# CS32F031x register map
File version: 1.0
Registers are 32-bit, read-write, reset 0x0 unless marked. A register's access mark holds for its fields unless they carry their own. Offsets are from the block's base; [hi:lo] are bit positions; lines under a group give offsets from that group; {n}, {i} and the like mark numbered series.

## ADC — Analog-to-digital converter
Base 0x40012400
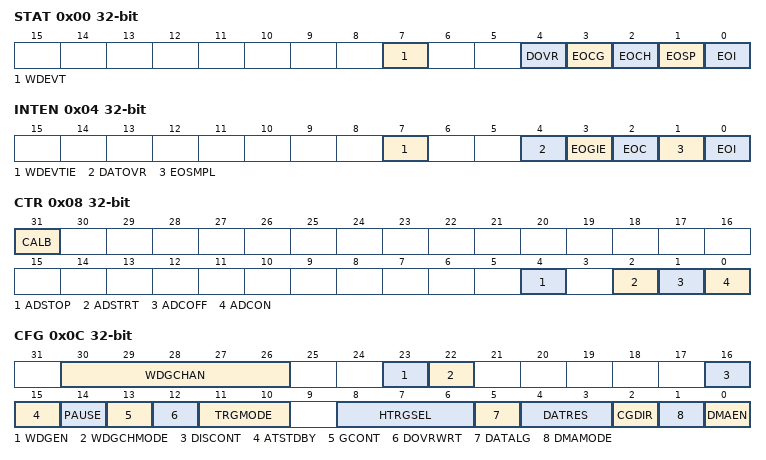
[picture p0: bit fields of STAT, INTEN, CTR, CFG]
0x00 STAT — ADC status register
  [7] WDEVT — analog watchdog event flag
  [4] DOVR — ADC data overrun flag
  [3] EOCG — End of conversion group flag
  [2] EOCH — End of channel conversion flag
  [1] EOSP — End of sampling phase flag
  [0] EOI — End of ADC initialization
0x04 INTEN — ADC interrupt enable register
  [7] WDEVTIE — analog watchdog event interrupt enable
  [4] DATOVR — ADC data overrun interrupt enable
  [3] EOGIE — End of conversion group interrupt enable
  [2] EOC — End of channel conversion interrupt enable
  [1] EOSMPL — End of sampling phase interrupt enable
  [0] EOI — End of ADC initialization interrupt enable
0x08 CTR — ADC general control register
  [31] CALB — ADC calibration control
  [4] ADSTOP — ADC stop conversion command
  [2] ADSTRT — ADC start conversion command
  [1] ADCOFF — ADC power off command
  [0] ADCON — ADC power on command
0x0C CFG — configuration register 1
  [30:26] WDGCHAN — Analog watchdog monitor channel selection
  [23] WDGEN — Analog watchdog enable
  [22] WDGCHMODE — Analog watchdog channel monitor mode
  [16] DISCONT — Discontinuous conversion mode
  [15] ATSTDBY — auto standby mode
  [14] PAUSE — conversion pause mode
  [13] GCONT — Group conversion Single/continuous mode
  [12] DOVRWRT — Coversion data overrun overwriten mode
  [11:10] TRGMODE — Coverstion Trigger mode selection
  [8:6] HTRGSEL — Hardware trigger source selection
  [5] DATALG — Coversion data format alignment
  [4:3] DATRES — Coversion data reselution
  [2] CGDIR — Coveration group sequence direction
  [1] DMAMODE — Direct memory access single/circle mode
  [0] DMAEN — Direct memory access enable
0x10 CLK reset 0x8000 — clock source register
  [31:30] CKSRC — ADC clock source selection
0x14 SMPLR — sampling time register
  [2:0] SMPLT — Sampling time selection
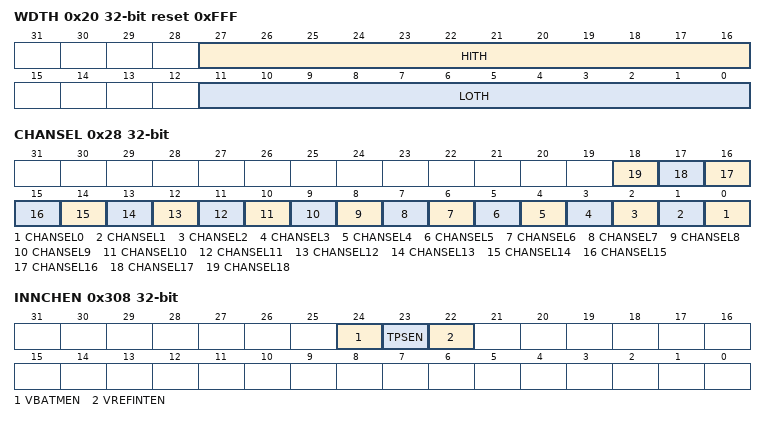
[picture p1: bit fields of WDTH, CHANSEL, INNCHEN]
0x20 WDTH reset 0xFFF — Analog watchdog threshold register
  [27:16] HITH — Analog watchdog higher threshold
  [11:0] LOTH — Analog watchdog lower threshold
0x28 CHANSEL — conversion channel selection register
  [n] CHANSEL{n} (n=0..18) — conversion channel selection x
0x40 OUTDAT ro — conversion output data register
  [15:0] OUTDAT — conversion output data
0x308 INNCHEN — internal conversion channel enable register
  [24] VBATMEN — VBAT monitor enable
  [23] TPSEN — Temperature sensor enable
  [22] VREFINTEN — VREFINT enable

## TIM15 — General-purpose-timers
Base 0x40014000
Same registers: TIM16 0x40014400, TIM17 0x40014800
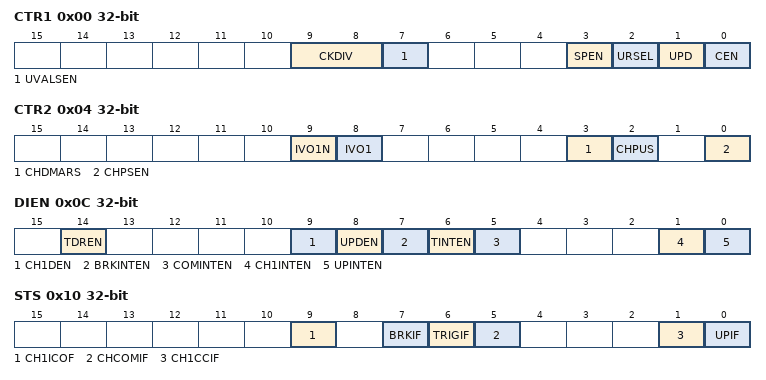
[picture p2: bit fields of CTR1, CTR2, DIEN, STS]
0x00 CTR1 — control register 1
  [9:8] CKDIV — Clock division
  [7] UVALSEN — UVAL shadow enable
  [3] SPEN — Single pulse enable
  [2] URSEL — Update request selection
  [1] UPD — Update disable
  [0] CEN — Counter enable
0x04 CTR2 — control register 2
  [9] IVO1N — Idle value output of channel 1 complementary
  [8] IVO1 — Idle value output of channel 1
  [3] CHDMARS — DMA request source of channel
  [2] CHPUS — Preload update source of channel
  [0] CHPSEN — Preload shadow enable of channel
0x0C DIEN — DMA and interrupt enable register
  [14] TDREN — Enable bit for trigger DMA request
  [9] CH1DEN — Enable bit for channel 1 DMA request
  [8] UPDEN — Enable bit for update DMA request
  [7] BRKINTEN — Enable bit for break interrupt
  [6] TINTEN — Enable bit for trigger interrupt
  [5] COMINTEN — Enable bit for COM event interrupt
  [1] CH1INTEN — Enable bit for channel 1 interrupt
  [0] UPINTEN — Enable bit for update interrupt
0x10 STS — status register
  [9] CH1ICOF — Channel 1 input capture overflow
  [7] BRKIF — Interrupt flag of break
  [6] TRIGIF — Interrupt flag of trigger
  [5] CHCOMIF — channel communication event interrupt flag
  [1] CH1CCIF — Channel 1 capture compare interrupt flag
  [0] UPIF — Interrupt flag of update
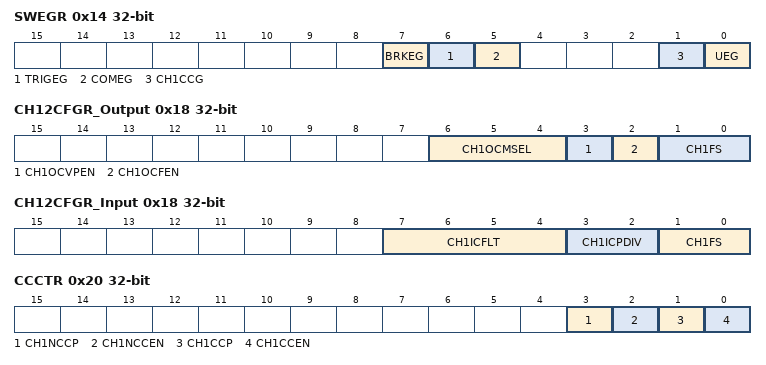
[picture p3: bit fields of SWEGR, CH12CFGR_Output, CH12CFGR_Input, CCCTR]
0x14 SWEGR wo — software event generation register
  [7] BRKEG — Break event generation
  [6] TRIGEG — Trigger event generation
  [5] COMEG — COM event generation
  [1] CH1CCG — Channel 1 capture compare event generation
  [0] UEG — Update event generation
0x18 CH12CFGR_Output — channel 1 and channel 2 configuration register (output mode)
  [6:4] CH1OCMSEL — Channel 1 output compare mode selection
  [3] CH1OCVPEN — Channel 1 output compare value preload enable
  [2] CH1OCFEN — Channel 1 output compare fast enable
  [1:0] CH1FS — Channel 1 function selection
0x18 CH12CFGR_Input (alternate view of CH12CFGR_Output) — channel 1 and channel 2 configuration register (input mode)
  [7:4] CH1ICFLT — Channel 1 input capture filter
  [3:2] CH1ICPDIV — Channel 1 input capture pre-divide
  [1:0] CH1FS — Channel 1 function selection
0x20 CCCTR — channel capture compare control register
  [3] CH1NCCP — Channel 1 complementary capture compare Polarity
  [2] CH1NCCEN — Channel 1 complementary capture compare enable
  [1] CH1CCP — Channel 1 capture compare polarity
  [0] CH1CCEN — Channel 1 capture compare enable
0x24 CNT — counter
  [15:0] CNT
0x28 PDIV — pre-divider
  [15:0] PDIV
0x2C UVAL — counter update register
  [15:0] UVAL — Counter update value
0x30 UVALREP — counter update register
  [7:0] UVALREP — counter update repetition value
0x34 CH1CCVAL — channel 1 capture compare value register
  [15:0] CH1CCVAL — channel 1 capture compare value
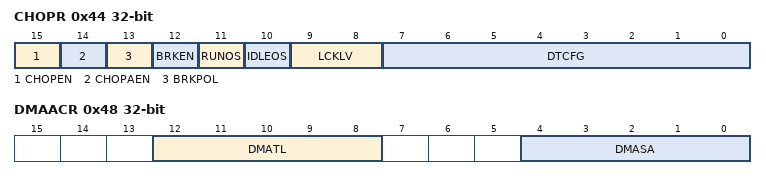
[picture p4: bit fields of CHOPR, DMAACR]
0x44 CHOPR — output protect register
  [15] CHOPEN — Channel output pad enable
  [14] CHOPAEN — Channel output pad auto enable
  [13] BRKPOL — Break polarity
  [12] BRKEN — Break enable
  [11] RUNOS — Run mode off-state control
  [10] IDLEOS — Idle mode off-state control
  [9:8] LCKLV — Lock level control
  [7:0] DTCFG — Dead-time configuration
0x48 DMAACR — DMA access configuration register
  [12:8] DMATL — DMA transfer length
  [4:0] DMASA — DMA start address
0x4C DMAIR — DMA access interface register
  [15:0] DMAI — DMA access interface

## TIM6 — General-purpose-timers
Base 0x40001000
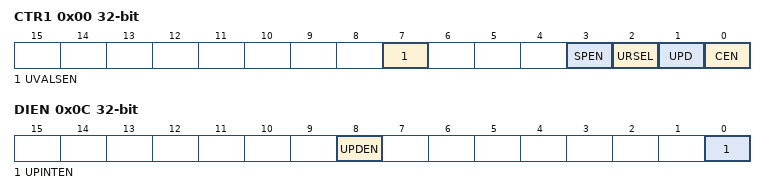
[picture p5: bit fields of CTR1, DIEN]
0x00 CTR1 — control register 1
  [7] UVALSEN — UVAL shadow enable
  [3] SPEN — Single pulse enable
  [2] URSEL — Update request selection
  [1] UPD — Update disable
  [0] CEN — Counter enable
0x04 CTR2 — control register 2
  [6:4] MMTOC — Master mode trigger out control
0x0C DIEN — DMA and interrupt enable register
  [8] UPDEN — Enable bit for update DMA request
  [0] UPINTEN — Enable bit for update interrupt
0x10 STS — status register
  [0] UPIF — Interrupt flag of update
0x14 SWEGR wo — software event generation register
  [0] UEG — Update event generation
0x24 CNT — counter
  [15:0] CNT
0x28 PDIV — pre-divider
  [15:0] PDIV
0x2C UVAL — counter update register
  [15:0] UVAL — Counter update value

## FMC — FLASH Memory Control
Base 0x40022000
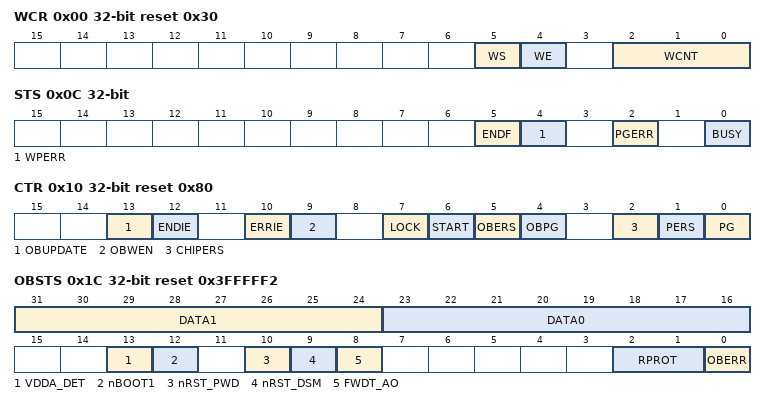
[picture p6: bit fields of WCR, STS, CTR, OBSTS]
0x00 WCR access per field reset 0x30 — Flash access control register
  [5] WS ro — FMC wait status
  [4] WE rw — FMC wait enable
  [2:0] WCNT rw — FMC wait conuter
0x04 CCODE wo — Control code register
  [31:0] CCODE — Control code
0x08 OBCCODE wo — Option Byte Control code register
  [31:0] OBCCODE — Option Byte Control code
0x0C STS access per field — status register
  [5] ENDF rw — End of operation
  [4] WPERR rw — Erase/Program protection error
  [2] PGERR rw — Program error
  [0] BUSY ro
0x10 CTR reset 0x80 — FMC control register
  [13] OBUPDATE — Update option byte
  [12] ENDIE — End of operation interrupt enable
  [10] ERRIE — Error interrupt enable
  [9] OBWEN — Option byte erase/program enable
  [7] LOCK
  [6] START — Start of erase
  [5] OBERS — Option byte erase command
  [4] OBPG — Option byte programm command
  [2] CHIPERS — Main flash CHIP ERASE
  [1] PERS — Flash page erase
  [0] PG — Main flash program
0x14 ERSADR wo — Flash erase address register
  [31:0] ERSADR — Flash erase address
0x1C OBSTS ro reset 0x3FFFFF2 — Option byte status register
  [31:24] DATA1
  [23:16] DATA0
  [13] VDDA_DET
  [12] nBOOT1
  [10] nRST_PWD
  [9] nRST_DSM
  [8] FWDT_AO
  [2:1] RPROT
  [0] OBERR — Option byte error
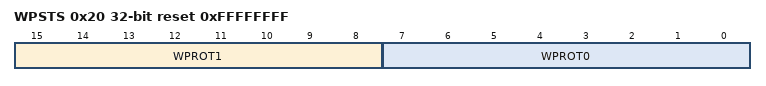
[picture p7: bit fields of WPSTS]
0x20 WPSTS ro reset 0xFFFFFFFF — Write protection status register
  [15:8] WPROT1 — Write protect byte 1
  [7:0] WPROT0 — Write protect byte 0

## DBG — Debug support
Base 0x40015800
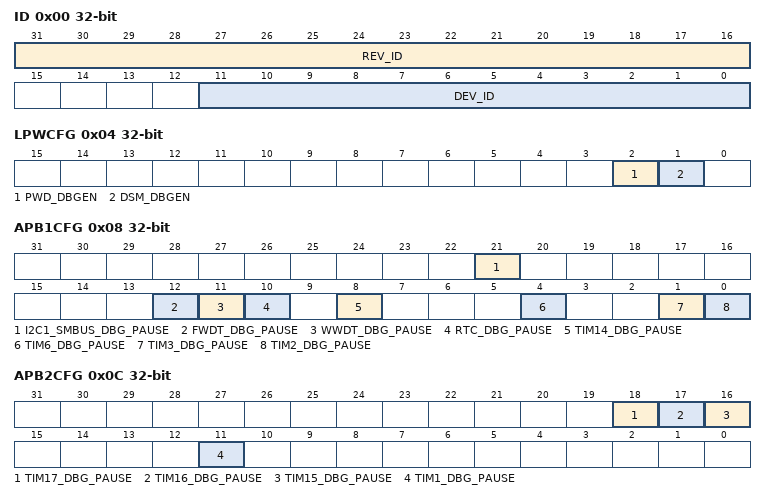
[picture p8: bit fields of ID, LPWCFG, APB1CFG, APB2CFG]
0x00 ID ro — MCU Device ID Code Register
  [31:16] REV_ID — Revision identifier
  [11:0] DEV_ID — Device Identifier
0x04 LPWCFG — Debug support for low power configuration register
  [2] PWD_DBGEN — Debug Down Power Mode
  [1] DSM_DBGEN — Debug Deep Sleep Mode
0x08 APB1CFG — Debug support for apb1 peripherals configuration register
  [21] I2C1_SMBUS_DBG_PAUSE — SMBUS timeout counter paused when system is in debug mode
  [12] FWDT_DBG_PAUSE — Free watchdog paused when system is in debug mode
  [11] WWDT_DBG_PAUSE — window watchdog paused when system is in debug mode
  [10] RTC_DBG_PAUSE — RTC paused when system is in debug mode
  [8] TIM14_DBG_PAUSE — TIM14 counter when system is in debug mode
  [4] TIM6_DBG_PAUSE — TIM6 counter paused when system is in debug mode
  [1] TIM3_DBG_PAUSE — TIM3 counter paused when system is in debug mode
  [0] TIM2_DBG_PAUSE — TIM2 counter paused when system is in debug mode
0x0C APB2CFG — Debug support for apb2 peripherals configuration register
  [18] TIM17_DBG_PAUSE — TIM17 counter paused when system is in debug mode
  [17] TIM16_DBG_PAUSE — TIM16 counter paused when system is in debug mode
  [16] TIM15_DBG_PAUSE — TIM15 counter paused when system is in debug mode
  [11] TIM1_DBG_PAUSE — TIM1 counter paused when system is in debug mode
